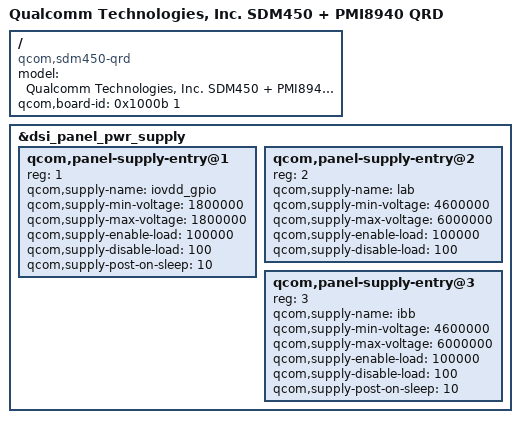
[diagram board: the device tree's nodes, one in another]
/*
 * Copyright (c) 2017, The Linux Foundation. All rights reserved.
 * Copyright (C) 2019 XiaoMi, Inc.
 *
 * This program is free software; you can redistribute it and/or modify
 * it under the terms of the GNU General Public License version 2 and
 * only version 2 as published by the Free Software Foundation.
 *
 * This program is distributed in the hope that it will be useful,
 * but WITHOUT ANY WARRANTY; without even the implied warranty of
 * MERCHANTABILITY or FITNESS FOR A PARTICULAR PURPOSE.  See the
 * GNU General Public License for more details.
 */

/dts-v1/;

#include "sdm450.dtsi"
#include "msm8953-audio.dtsi"
#include "msm8953-mdss-panels.dtsi"
#include "msm8953-pinctrl.dtsi"
#include "msm8953-pm.dtsi"
#include "msm8953-regulator.dtsi"
#include "msm-pm8953.dtsi"
#include "msm-pmi8940.dtsi"

/ {
	model = "Qualcomm Technologies, Inc. SDM450 + PMI8940 QRD";
	compatible = "qcom,sdm450-qrd", "qcom,sdm450", "qcom,qrd";
	qcom,board-id = <0x1000b 1>;
};

&dsi_panel_pwr_supply {
	qcom,panel-supply-entry@1 {
		reg = <1>;
		qcom,supply-name = "iovdd_gpio";
		qcom,supply-min-voltage = <1800000>;
		qcom,supply-max-voltage = <1800000>;
		qcom,supply-enable-load = <100000>;
		qcom,supply-disable-load = <100>;
		qcom,supply-post-on-sleep = <10>;
	};

	qcom,panel-supply-entry@2 {
		reg = <2>;
		qcom,supply-name = "lab";
		qcom,supply-min-voltage = <4600000>;
		qcom,supply-max-voltage = <6000000>;
		qcom,supply-enable-load = <100000>;
		qcom,supply-disable-load = <100>;
	};

	qcom,panel-supply-entry@3 {
		reg = <3>;
		qcom,supply-name = "ibb";
		qcom,supply-min-voltage = <4600000>;
		qcom,supply-max-voltage = <6000000>;
		qcom,supply-enable-load = <100000>;
		qcom,supply-disable-load = <100>;
		qcom,supply-post-on-sleep = <10>;
	};
};

#include "rosy/rosy-overlay.dtsi"
